# ALWAYS_ON_PRM register map
Vendor: Texas Instruments
Peripheral module from a debugger description file (folder omap4430).
Registers are 32-bit, access not given, reset 0x1 unless marked. A register's access mark holds for its fields unless they carry their own. Offsets are as the file gives them; lines under a group give offsets from that group; [hi:lo] are bit positions; {n}, {i} and the like mark numbered series; 'fields as' and 'values as' point back to an identical list; <NAME> marks a mode.

## ALWAYS_ON_PRM
0x28 PM_ALWON_SR_MPU_WKDEP — This register controls wakeup dependency based on SR_MPU service requests.
  [0] WKUPDEP_SR_MPU_MPU — Wakeup dependency from SR_MPU module (softwareakeup signal) towards MPU + L3_1 + L4_CFG domains (access R Rreturns1s)
    1=WKUPDEP_SR_MPU_MPU_1_r (Dependency is enabled)
0x2C RM_ALWON_SR_MPU_CONTEXT — This register contains dedicated SR_MPU context statuses. [warm reset insensitive]
  [0] LOSTCONTEXT_DFF — Specify if DFF-based context has been lost due to a previous power transition or other reset source. (set upon assertion of Always_on_CORE_RST signal) (access RW W1toClr)
    0=Context has been maintained; 1=Context has been lost
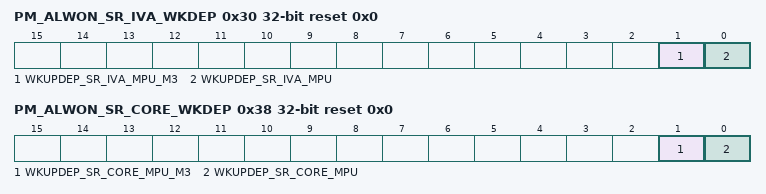
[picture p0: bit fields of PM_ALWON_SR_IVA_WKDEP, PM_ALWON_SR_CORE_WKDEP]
0x30 PM_ALWON_SR_IVA_WKDEP access per field reset 0x0 — This register controls wakeup dependency based on SR_IVA service requests.
  [1] WKUPDEP_SR_IVA_MPU_M3 rw — Wakeup dependency from SR_IVA module (softwareakeup signal) towards MPU_A3 + L3_2 + L3_1 + L4_CFG domains
    0=Dependency is disabled; 1=Dependency is enabled
  [0] WKUPDEP_SR_IVA_MPU rw — Wakeup dependency from SR_IVA module (softwareakeup signal) towards MPU + L3_1 + L4_CFG domains
    0=Dependency is disabled; 1=Dependency is enabled
0x34 RM_ALWON_SR_IVA_CONTEXT — This register contains dedicated SR_IVA context statuses. [warm reset insensitive]
  fields as RM_ALWON_SR_MPU_CONTEXT
0x38 PM_ALWON_SR_CORE_WKDEP access per field reset 0x0 — This register controls wakeup dependency based on SR_CORE service requests.
  [1] WKUPDEP_SR_CORE_MPU_M3 rw — Wakeup dependency from SR_CORE module (softwareakeup signal) towards MPU_A3 + L3_2 + L3_1 + L4_CFG domains
    0=Dependency is disabled; 1=Dependency is enabled
  [0] WKUPDEP_SR_CORE_MPU rw — Wakeup dependency from SR_CORE module (softwareakeup signal) towards MPU + L3_1 + L4_CFG domains
    0=Dependency is disabled; 1=Dependency is enabled
0x3C RM_ALWON_SR_CORE_CONTEXT — This register contains dedicated SR_CORE context statuses. [warm reset insensitive]
  fields as RM_ALWON_SR_MPU_CONTEXT
